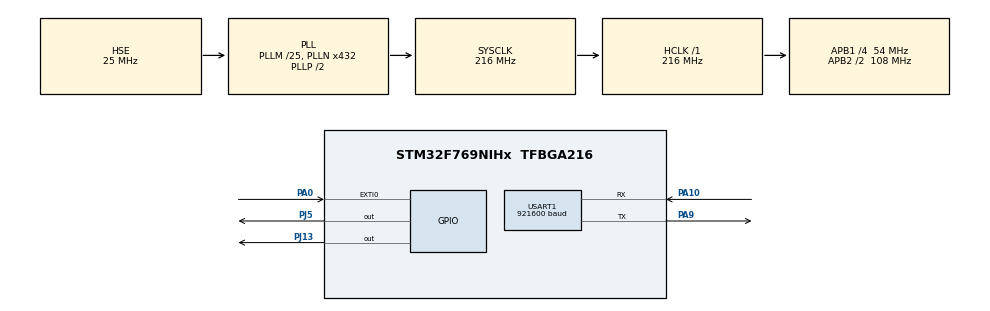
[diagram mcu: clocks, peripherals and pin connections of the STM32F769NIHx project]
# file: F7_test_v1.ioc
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Mcu.Family=STM32F7
RCC.CortexFreq_Value=216000000
Dma.USART1_TX.1.MemInc=DMA_MINC_ENABLE
NVIC.TIM6_DAC_IRQn=true\:0\:0\:false\:false\:true\:true\:true
USART1.BaudRate=921600
PA0/WKUP.Signal=GPXTI0
PC14/OSC32_IN.Mode=LSE-External-Oscillator
RCC.SYSCLKSource=RCC_SYSCLKSOURCE_PLLCLK
ProjectManager.StackSize=0x400
PH0/OSC_IN.Mode=HSE-External-Oscillator
RCC.HCLKFreq_Value=216000000
RCC.APB2TimFreq_Value=216000000
PH1/OSC_OUT.Signal=RCC_OSC_OUT
RCC.AHBFreq_Value=216000000
Dma.USART1_RX.0.Priority=DMA_PRIORITY_LOW
RCC.HSE_VALUE=25000000
PA14.Mode=Serial_Wire
TIM6.Period=50000
PA0/WKUP.GPIO_ModeDefaultEXTI=GPIO_MODE_IT_FALLING
Dma.USART1_RX.0.MemInc=DMA_MINC_ENABLE
PH1/OSC_OUT.Mode=HSE-External-Oscillator
Dma.USART1_TX.1.PeriphDataAlignment=DMA_PDATAALIGN_BYTE
Mcu.Package=TFBGA216
NVIC.DMA2_Stream7_IRQn=true\:0\:0\:false\:false\:true\:false\:true
PC14/OSC32_IN.Signal=RCC_OSC32_IN
PA10.Signal=USART1_RX
Dma.USART1_RX.0.FIFOMode=DMA_FIFOMODE_DISABLE
RCC.APB2CLKDivider=RCC_HCLK_DIV2
NVIC.DMA2_Stream2_IRQn=true\:0\:0\:false\:false\:true\:false\:true
Dma.Request1=USART1_TX
RCC.APB1TimFreq_Value=108000000
Dma.USART1_RX.0.Mode=DMA_CIRCULAR
Dma.USART1_TX.1.Priority=DMA_PRIORITY_LOW
NVIC.USART1_IRQn=true\:0\:0\:false\:false\:true\:true\:true
Dma.Request0=USART1_RX
Dma.USART1_RX.0.Instance=DMA2_Stream2
Dma.USART1_TX.1.Direction=DMA_MEMORY_TO_PERIPH
RCC.PLLSourceVirtual=RCC_PLLSOURCE_HSE
Dma.USART1_TX.1.Instance=DMA2_Stream7
Dma.USART1_RX.0.PeriphDataAlignment=DMA_PDATAALIGN_BYTE
PA10.Mode=Asynchronous
TIM6.Prescaler=53
VP_TIM6_VS_ClockSourceINT.Mode=Enable_Timer
RCC.APB1CLKDivider=RCC_HCLK_DIV4
USART1.VirtualMode-Asynchronous=VM_ASYNC
PA13.Signal=SYS_JTMS-SWDIO
PA9.Mode=Asynchronous
ProjectManager.TargetToolchain=STM32CubeIDE
Dma.USART1_RX.0.Direction=DMA_PERIPH_TO_MEMORY
PA9.Signal=USART1_TX
Dma.USART1_TX.1.FIFOMode=DMA_FIFOMODE_DISABLE
RCC.USBFreq_Value=216000000
Dma.USART1_RX.0.PeriphInc=DMA_PINC_DISABLE
Dma.USART1_TX.1.MemDataAlignment=DMA_MDATAALIGN_BYTE
board=custom
RCC.VCOOutputFreq_Value=432000000
PH0/OSC_IN.Signal=RCC_OSC_IN
RCC.APB2Freq_Value=108000000
Dma.USART1_RX.0.MemDataAlignment=DMA_MDATAALIGN_BYTE
PA13.Mode=Serial_Wire
Mcu.Name=STM32F769NIHx
NVIC.EXTI0_IRQn=true\:0\:0\:false\:false\:true\:true\:true
RCC.SYSCLKFreq_VALUE=216000000
Dma.USART1_TX.1.Mode=DMA_NORMAL
PC15/OSC32_OUT.Mode=LSE-External-Oscillator
PJ5.Signal=GPIO_Output
PA14.Signal=SYS_JTCK-SWCLK
ProjectManager.HeapSize=0x200
Dma.USART1_TX.1.PeriphInc=DMA_PINC_DISABLE
RCC.HSI_VALUE=16000000
NVIC.PriorityGroup=NVIC_PRIORITYGROUP_4
RCC.PLLM=25
RCC.PLLN=432
PC15/OSC32_OUT.Signal=RCC_OSC32_OUT
RCC.APB1Freq_Value=54000000
PJ13.Signal=GPIO_Output

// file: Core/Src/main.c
/* USER CODE BEGIN Header */
/**
  ******************************************************************************
  * @file           : main.c
  * @brief          : Main program body
  ******************************************************************************
  * @attention
  *
  * <h2><center>&copy; Copyright (c) 2020 STMicroelectronics.
  * All rights reserved.</center></h2>
  *
  * This software component is licensed by ST under BSD 3-Clause license,
  * the "License"; You may not use this file except in compliance with the
  * License. You may obtain a copy of the License at:
  *                        opensource.org/licenses/BSD-3-Clause
  *
  ******************************************************************************
  */
/* USER CODE END Header */

#include "main.h"
#include "dma.h"
#include "tim.h"
#include "usart.h"
#include "gpio.h"

/* USER CODE BEGIN Includes */
#include "stdio.h"
#include "math.h"

#include "DC_MPC_Controller_Simp/DC_MPC_Controller_Simp_main.h"
/* USER CODE END Includes */

/* USER CODE BEGIN PV */

extern float ReBuf[];
extern float SendBuf[];
/* USER CODE END PV */

void SystemClock_Config(void);

int main(void)
{

  /* MCU Configuration--------------------------------------------------------*/

  /* Reset of all peripherals, Initializes the Flash interface and the Systick. */
  HAL_Init();

  /* Configure the system clock */
  SystemClock_Config();

  /* Initialize all configured peripherals */
  MX_GPIO_Init();
  MX_DMA_Init();
  MX_TIM6_Init();
  MX_USART1_UART_Init();
  /* USER CODE BEGIN 2 */
  HAL_TIM_Base_Start(&htim6);

  DC_MPC_Controller_initialize();
  EKF_MPC_Cal();

    HAL_UART_Receive_DMA(&huart1, ReBuf, 36);	//Receive 9 single values

  /* USER CODE END 2 */

  /* Infinite loop */
  while (1)
  {

  }
}

void SystemClock_Config(void)
{
  RCC_OscInitTypeDef RCC_OscInitStruct = {0};
  RCC_ClkInitTypeDef RCC_ClkInitStruct = {0};
  RCC_PeriphCLKInitTypeDef PeriphClkInitStruct = {0};

  /** Configure LSE Drive Capability
  */
  HAL_PWR_EnableBkUpAccess();
  /** Configure the main internal regulator output voltage
  */
  __HAL_RCC_PWR_CLK_ENABLE();
  __HAL_PWR_VOLTAGESCALING_CONFIG(PWR_REGULATOR_VOLTAGE_SCALE1);
  /** Initializes the CPU, AHB and APB busses clocks
  */
  RCC_OscInitStruct.OscillatorType = RCC_OSCILLATORTYPE_HSE;
  RCC_OscInitStruct.HSEState = RCC_HSE_ON;
  RCC_OscInitStruct.PLL.PLLState = RCC_PLL_ON;
  RCC_OscInitStruct.PLL.PLLSource = RCC_PLLSOURCE_HSE;
  RCC_OscInitStruct.PLL.PLLM = 25;
  RCC_OscInitStruct.PLL.PLLN = 432;
  RCC_OscInitStruct.PLL.PLLP = RCC_PLLP_DIV2;
  RCC_OscInitStruct.PLL.PLLQ = 2;
  if (HAL_RCC_OscConfig(&RCC_OscInitStruct) != HAL_OK)
  {
    Error_Handler();
  }
  /** Activate the Over-Drive mode
  */
  if (HAL_PWREx_EnableOverDrive() != HAL_OK)
  {
    Error_Handler();
  }
  /** Initializes the CPU, AHB and APB busses clocks
  */
  RCC_ClkInitStruct.ClockType = RCC_CLOCKTYPE_HCLK|RCC_CLOCKTYPE_SYSCLK
                              |RCC_CLOCKTYPE_PCLK1|RCC_CLOCKTYPE_PCLK2;
  RCC_ClkInitStruct.SYSCLKSource = RCC_SYSCLKSOURCE_PLLCLK;
  RCC_ClkInitStruct.AHBCLKDivider = RCC_SYSCLK_DIV1;
  RCC_ClkInitStruct.APB1CLKDivider = RCC_HCLK_DIV4;
  RCC_ClkInitStruct.APB2CLKDivider = RCC_HCLK_DIV2;

  if (HAL_RCC_ClockConfig(&RCC_ClkInitStruct, FLASH_LATENCY_7) != HAL_OK)
  {
    Error_Handler();
  }
  PeriphClkInitStruct.PeriphClockSelection = RCC_PERIPHCLK_USART1;
  PeriphClkInitStruct.Usart1ClockSelection = RCC_USART1CLKSOURCE_PCLK2;
  if (HAL_RCCEx_PeriphCLKConfig(&PeriphClkInitStruct) != HAL_OK)
  {
    Error_Handler();
  }
}

/* USER CODE BEGIN 4 */
void HAL_UART_RxCpltCallback(UART_HandleTypeDef *huart)
{
	HAL_GPIO_WritePin(GPIOJ,GPIO_PIN_5, 1);

	DC_MPC_Simp_Step();

	HAL_UART_Transmit_DMA(&huart1, SendBuf, 36);	//Send 9 single values

	HAL_GPIO_WritePin(GPIOJ,GPIO_PIN_5,0);

}

/* USER CODE END 4 */

void Error_Handler(void)
{
}

/************************ (C) COPYRIGHT STMicroelectronics *****END OF FILE****/
